# TestMCU register map
File version: 1.0
Test MCU for unit tests
Registers are 32-bit, read-write, reset 0x0 unless marked. A register's access mark holds for its fields unless they carry their own. Offsets are from the block's base; lines under a group give offsets from that group; [hi:lo] are bit positions; {n}, {i} and the like mark numbered series; 'fields as' and 'values as' point back to an identical list; <NAME> marks a mode.

## Memory map
{0x3FFFFC00+0x400*n} TIM{n} (n=1..2) — Timer {n}
0x40020000 GPIOA — General purpose I/O port A
0x40020400 GPIOB — General purpose I/O port B
0x40023800 RCC — Reset and clock control

## GPIOA — General purpose I/O port A
Base 0x40020000
Same registers: GPIOB 0x40020400
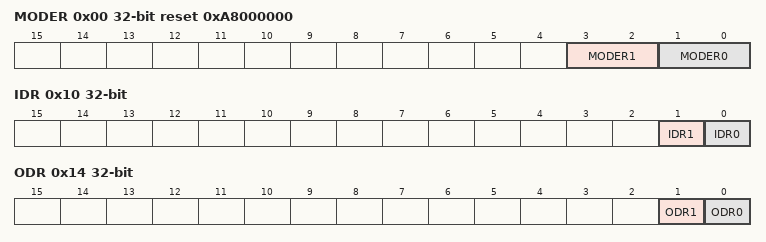
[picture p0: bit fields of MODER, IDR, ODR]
0x00 MODER reset 0xA8000000 — GPIO port mode register
  [3:2] MODER1 — Port x configuration bits (y = 1)
    0=Input mode; 1=Output (General purpose output mode); 2=Alternate function mode; 3=Analog mode
  [1:0] MODER0 — Port x configuration bits (y = 0)
    values as MODER1
0x10 IDR ro — GPIO port input data register
  [1] IDR1 — Port input data bit 1
  [0] IDR0 — Port input data bit 0
0x14 ODR — GPIO port output data register
  [1] ODR1 — Port output data bit 1
  [0] ODR0 — Port output data bit 0

## RCC — Reset and clock control
Base 0x40023800
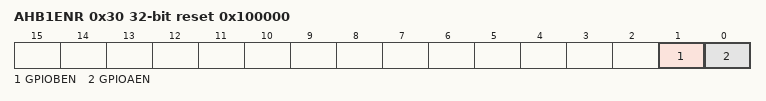
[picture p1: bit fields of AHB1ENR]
0x30 AHB1ENR reset 0x100000 — AHB1 peripheral clock enable register
  [1] GPIOBEN — IO port B clock enable
  [0] GPIOAEN — IO port A clock enable
    0=Disabled (Clock disabled); 1=Enabled (Clock enabled)

## TIM{n} — Timer {n}
Base 0x40000000; array of 2, step 0x400
0x00 CR1 — Control register 1
  [0] CEN — Counter enable
{0x30+4i} CCR{i} (i=1..2) — Capture/compare register {i}
  [15:0] CCR — Capture/compare value
